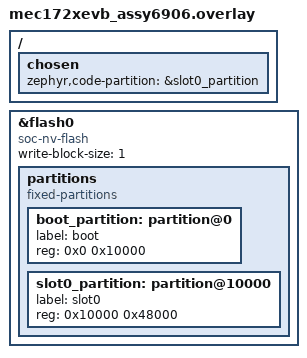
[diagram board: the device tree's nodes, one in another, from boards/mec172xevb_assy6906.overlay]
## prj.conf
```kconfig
CONFIG_BOOTLOADER_MCUBOOT=y
CONFIG_MCUBOOT_IMGTOOL_LOAD_ADDRESS=0xd0000
CONFIG_ROM_START_OFFSET=0x400

CONFIG_MCUBOOT_SIGNATURE_KEY_FILE="./bootloader/mcuboot/root-rsa-2048.pem"
```

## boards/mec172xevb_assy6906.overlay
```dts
/ {
	chosen {
		zephyr,code-partition = &slot0_partition;
	};
};

&flash0 {
	compatible = "soc-nv-flash";
	write-block-size = <1>;
	partitions {
		compatible = "fixed-partitions";
		#address-cells = <1>;
		#size-cells = <1>;

		boot_partition: partition@0 {
			label = "boot";
			reg = <0x0 0x10000>;
		};
		slot0_partition: partition@10000 {
			label = "slot0";
			reg = <0x10000 0x48000>;
		};
	};
};
```

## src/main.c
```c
/*
 * Copyright (c) 2017 Linaro, Ltd.
 *
 * SPDX-License-Identifier: Apache-2.0
 */

#include <zephyr/kernel.h>
#include <zephyr/sys/printk.h>

int main(void)
{
	printk("Hello World from %s on %s!\n",
	       MCUBOOT_HELLO_WORLD_FROM, CONFIG_BOARD);
}
```
